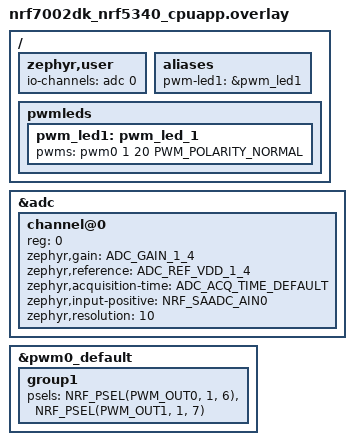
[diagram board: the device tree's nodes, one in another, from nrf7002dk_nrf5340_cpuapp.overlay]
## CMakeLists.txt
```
cmake_minimum_required(VERSION 3.20.0)
find_package(Zephyr REQUIRED HINTS $ENV{ZEPHYR_BASE})

project(light_app)

target_sources(app PRIVATE src/main.c)
```

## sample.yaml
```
sample:
  name: Light regulator on nRF7002 DK
tests:
  sample.drivers.lcd.hd44780:
    platform_allow: nrf7002dk_nrf5340_cpuapp nrf7002dk_nrf7001_nrf5340_cpuapp
    integration_platforms:
      - nrf7002dk_nrf5340_cpuapp
    tags: led
    harness: led
    depends_on: gpio adc
```

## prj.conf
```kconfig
CONFIG_PWM=y
CONFIG_ADC=y
```

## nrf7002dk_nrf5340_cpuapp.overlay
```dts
// To get started, press Ctrl+Space to bring up the completion menu and view the available nodes.

// You can also use the buttons in the sidebar to perform actions on nodes.
// Actions currently available include:

// * Enabling / disabling the node
// * Adding the bus to a bus
// * Removing the node
// * Connecting ADC channels

// For more help, browse the DeviceTree documentation at https://docs.zephyrproject.org/latest/guides/dts/index.html
// You can also visit the nRF DeviceTree extension documentation at https://nrfconnect.github.io/vscode-nrf-connect/devicetree/nrfdevicetree.html

/ {
	zephyr,user {
		io-channels = <&adc 0>;
	};
};

&adc {
	#address-cells = <1>;
	#size-cells = <0>;

	channel@0 {
		reg = <0>;
		zephyr,gain = "ADC_GAIN_1_4";
		zephyr,reference = "ADC_REF_VDD_1_4";
		zephyr,acquisition-time = <ADC_ACQ_TIME_DEFAULT>;
		zephyr,input-positive = <NRF_SAADC_AIN0>; /* P0.04 */
		zephyr,resolution = <10>;
	};
};

/ {
	/* These aliases are provided for compatibility with samples */
	aliases {
		pwm-led1 = &pwm_led1;
	};
};

&pwm0_default {
    group1 {
        psels = <NRF_PSEL(PWM_OUT0, 1, 6)>, <NRF_PSEL(PWM_OUT1, 1, 7)>;
    };
};

/ {
    pwmleds {
        pwm_led1: pwm_led_1 {
            pwms = <&pwm0 1 20 PWM_POLARITY_NORMAL>;
        };
    };
};
```

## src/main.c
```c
#include <zephyr/kernel.h>
#include <zephyr/sys/printk.h>
#include <zephyr/drivers/pwm.h>
#include <zephyr/devicetree.h>
#include <zephyr/drivers/adc.h>

#if !DT_NODE_EXISTS(DT_PATH(zephyr_user)) || \
    !DT_NODE_HAS_PROP(DT_PATH(zephyr_user), io_channels)
#error "No suitable devicetree overlay specified"
#endif

#define DT_SPEC_AND_COMMA(node_id, prop, idx) \
    ADC_DT_SPEC_GET_BY_IDX(node_id, idx),

#define PWM_MAX 253
#define TIMER_INTERVAL_MSEC 200
#define BUFFER_SIZE 1
#define ADC_MAX 1023

static const struct pwm_dt_spec pwm_led = PWM_DT_SPEC_GET(DT_ALIAS(pwm_led1));
/* Data of ADC io-channels specified in devicetree. */
static const struct adc_dt_spec adc_channels[] = {
    DT_FOREACH_PROP_ELEM(DT_PATH(zephyr_user), io_channels,
                DT_SPEC_AND_COMMA)
};
struct k_timer my_timer;
static int16_t m_sample_buffer[BUFFER_SIZE];

static int adc_sample(void)
{
    int status;
    struct adc_sequence sequence = {
        .buffer = &m_sample_buffer,
        /* buffer size in bytes, not number of samples */
        .buffer_size = sizeof(m_sample_buffer),
    };

    (void)adc_sequence_init_dt(&adc_channels[0], &sequence);

    status = adc_read(adc_channels[0].dev, &sequence);
    if (status < 0) {
        printk("Error %d: failed to read ADC\n", status);
    }

    return status;
}

void adc_sample_event(struct k_timer *timer_id){
    int status;
    int adc_value;

    // Read ADC value
    status = adc_sample();
    if (status) {
        printk("adc_read() failed with code %d\n", status);
        return;
    }

    // Check the ranges
    if (m_sample_buffer[0] < 0) {
        adc_value = 0;
    }
    else {
        adc_value = m_sample_buffer[0]; 
    }
    printk("ADC value %d\n", adc_value);

    // Calculate the PWM width
    uint32_t pwm_val = (uint32_t)(((float)PWM_MAX/ADC_MAX)*adc_value);
    if (pwm_val > PWM_MAX) {
        printk("Error: failed to set pulse width %d\n", pwm_val);
        return;
    }

    // Set the PWM width
    printk("Setting pulse to %d\n", pwm_val);
    status = pwm_set_dt(&pwm_led, PWM_MAX, pwm_val);
    if (status) {
        printk("Error %d: failed to set pulse width\n", status);
    }
}

void main(void)
{
    printk("PWM Application has started!\r\n");
    int status;

    // PWM setup
	if (!device_is_ready(pwm_led.dev)) {
		printk("Error: PWM device %s is not ready\n",
		       pwm_led.dev->name);
		return 0;
	}

    // ADC setup
    if (!device_is_ready(adc_channels[0].dev)) {
        printk("Error %d: failed to ADC\n", status);
        return;
    }

    status = adc_channel_setup_dt(&adc_channels[0]);
    if (status < 0) {
        printk("Error %d: failed to ADC\n", status);
        return;
    }

    // Timer setup
    k_timer_init(&my_timer, adc_sample_event, NULL);
    k_timer_start(&my_timer, K_MSEC(TIMER_INTERVAL_MSEC), K_MSEC(TIMER_INTERVAL_MSEC));
}
```
